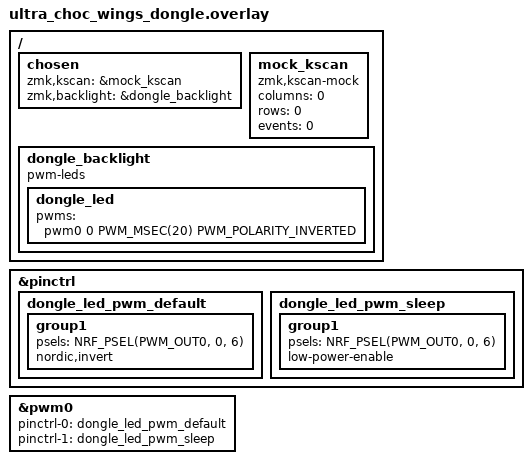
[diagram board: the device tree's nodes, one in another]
/*
 * The dongle has no keys. It is a bare XIAO nRF52840 on USB acting as the
 * split central. Its backlight is the XIAO's own LED, so the backlight keys in
 * the keymap have something to drive on the central; the halves light their
 * per-key LEDs from the same commands.
 */
#include "ultra_choc_wings.dtsi"
#include <dt-bindings/led/led.h>

/ {
    chosen {
        zmk,kscan = &mock_kscan;
        zmk,backlight = &dongle_backlight;
    };

    mock_kscan: mock_kscan {
        compatible = "zmk,kscan-mock";
        columns = <0>;
        rows = <0>;
        events = <0>;
    };

    dongle_backlight: dongle_backlight {
        compatible = "pwm-leds";
        dongle_led {
            pwms = <&pwm0 0 PWM_MSEC(20) PWM_POLARITY_INVERTED>;
        };
    };
};

/* Blue user LED of the XIAO (P0.06, active low). */
&pinctrl {
    dongle_led_pwm_default: dongle_led_pwm_default {
        group1 {
            psels = <NRF_PSEL(PWM_OUT0, 0, 6)>;
            nordic,invert;
        };
    };

    dongle_led_pwm_sleep: dongle_led_pwm_sleep {
        group1 {
            psels = <NRF_PSEL(PWM_OUT0, 0, 6)>;
            low-power-enable;
        };
    };
};

&pwm0 {
    status = "okay";
    pinctrl-0 = <&dongle_led_pwm_default>;
    pinctrl-1 = <&dongle_led_pwm_sleep>;
    pinctrl-names = "default", "sleep";
};
